# D1H register map
Vendor: Allwinner; File version: 1.0
Registers are 32-bit, read-write, reset 0x0 unless marked. A register's access mark holds for its fields unless they carry their own. Offsets are from the block's base; [hi:lo] are bit positions; {n}, {i} and the like mark numbered series; 'fields as' and 'values as' point back to an identical list.

## HS_TIMER — High Speed Timer
Base 0x03008000
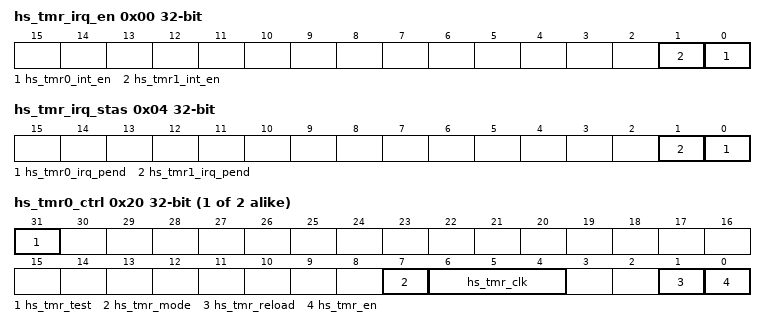
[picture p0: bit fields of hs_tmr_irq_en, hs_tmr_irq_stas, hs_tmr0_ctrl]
0x00 hs_tmr_irq_en — HS Timer IRQ Enable Register
  [n] hs_tmr{n}_int_en (n=0..1) — HSTimer Interrupt Enable
    0=DISABLED; 1=ENABLED
0x04 hs_tmr_irq_stas — HS Timer Status Register
  [n] hs_tmr{n}_irq_pend (n=0..1) write-1-clears — HSTimer IRQ Pending
    0=NO_EFFECT; 1=PENDING
{0x20+0x20*i} hs_tmr{i}_ctrl (i=0..1) — HS Timer Control Register
  [31] hs_tmr_test — Select the operating mode for HSTimer
    0=NORMAL; 1=TEST
  [7] hs_tmr_mode — Select the timing mode for HSTimer
    0=PERIODIC; 1=ONE_SHOT
  [6:4] hs_tmr_clk — Select the pre-scale for the HSTimer clock sources
    0=P1; 1=P2; 2=P4; 3=P8; 4=P16
  [1] hs_tmr_reload write-1-sets — HSTimer Reload
    0=NO_EFFECT; 1=RELOAD
  [0] hs_tmr_en — HSTimer Enable
    0=STOP_PAUSE; 1=START
{0x24+0x20*i} hs_tmr{i}_intv_lo (i=0..1) — HS Timer Interval Value Low Register
{0x28+0x20*i} hs_tmr{i}_intv_hi (i=0..1) — HS Timer Interval Value High Register
  [23:0] hs_tmr_intv_value_hi
{0x2C+0x20*i} hs_tmr{i}_curnt_lo (i=0..1) — HS Timer Current Value Low Register
{0x30+0x20*i} hs_tmr{i}_curnt_hi (i=0..1) — HS Timer Current Value High Register
  [23:0] hs_tmr_cur_value_hi

## PLIC — Platform Level Interrupt Control
Base 0x10000000
{0x0+4i} prio[{i}] (i=0..255) — Interrupt Priority Register
  [4:0] priority
    0=P0 (Priority 0 (never interrupt)); {v}=P{v} (Priority {v}) (v=1..31)
{0x1000+4i} ip[{i}] (i=0..8) — Interrupt Pending Register
{0x2000+4i} mie[{i}] (i=0..8) — Machine Mode Interrupt Enable Register
{0x2080+4i} sie[{i}] (i=0..8) — Supervisor Mode Interrupt Enable Register
0x1FFFFC ctrl — Control Register
  [0] ctrl — PLIC Control
    0=M (Only the machine mode can access to all registers in PLIC. Supervisor mode can only access the interrupt threshold register and the interrupt response/completion register.); 1=MS (The machine mode and the supervisor mode can access all registers. CTRL is accessible only in the machine mode.)
0x200000 mth — Machine Mode Priority Threshold Register
  fields as prio[0]
0x200004 mclaim — Machine Mode Claim/Complete Register
  [9:0] mclaim
0x201000 sth — Supervisor Mode Priority Threshold Register
  fields as prio[0]
0x201004 sclaim — Supervisor Mode Claim/Complete Register
  [9:0] sclaim

## THS — Thermal Sensor Controller
Base 0x02009400
0x00 ths_ctrl reset 0x1DF002F — THS Control Register
  [31:16] tacq — ADC acquire time . CLK_IN/(n + 1) . The default value is 2 us.
0x04 ths_en — THS Enable Register
  [0] ths_en — Enable temperature measurement sensor
    0=DISABLE; 1=ENABLE
0x08 ths_per reset 0x3A000 — THS Period Control Register
  [31:12] thermal_per — Temperature measurement period . 4096*(n + 1)/CLK_IN . The default value is 10 ms.
0x10 ths_data_intc — THS Data Interrupt Control Register
  [0] ths_data_irq_en — Enable the interrupt of sensor_data update . If enabled, when the measured sensor_data is updated, it will generate an interrupt.
    0=DISABLE; 1=ENABLE
0x14 ths_shut_intc — THS Shut Interrupt Control Register
  [0] shut_int_en — Enable the shutdown interrupt for the sensor
    0=DISABLE; 1=ENABLE
0x18 ths_alarm_intc — THS Alarm Interrupt Control Register
  [0] alarm_int_en — Enable the alarm interrupt for the sensor
    0=DISABLE; 1=ENABLE
0x20 ths_data_ints — THS Data Interrupt Status Register
  [0] ths_data_irq_sts write-1-clears — Indicates the pending status of the sensor's data interrupt. . Write 1 to clear the pending status.
    0=NO_EFFECT; 1=PENDING
0x24 ths_shut_ints — THS Shut Interrupt Status Register
  [0] shut_int_sts write-1-clears — Indicates the pending status of the sensor's shutdown interrupt. . Write 1 to clear the pending status.
    0=NO_EFFECT; 1=PENDING
0x28 ths_alarmo_ints — THS_ALARM0_INTS
  [0] alarm_off_sts write-1-clears — Alarm interrupt off pending for sensor . Write 1 to clear the pending status.
    0=NO_EFFECT; 1=PENDING
0x2C ths_alarm_ints — THS Alarm Interrupt Status Register
  [0] alarm_int_sts write-1-clears — Alarm interrupt pending for sensor . Write 1 to clear the pending status.
    0=NO_EFFECT; 1=PENDING
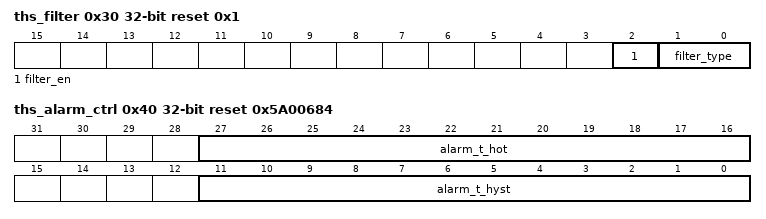
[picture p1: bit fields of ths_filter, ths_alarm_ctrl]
0x30 ths_filter reset 0x1 — THS Median Filter Control Register
  [2] filter_en — Filter enable
    0=DISABLE; 1=ENABLE
  [1:0] filter_type — Averaging filter type
    0=T2 (2); 1=T4 (4); 2=T8 (8); 3=T16 (16)
0x40 ths_alarm_ctrl reset 0x5A00684 — THS Alarm Threshold Control Register
  [27:16] alarm_t_hot — Thermal sensor alarm threshold for hot temperature
  [11:0] alarm_t_hyst — Thermal sensor alarm threshold for hysteresis temperature
0x80 ths_shutdown_ctrl reset 0x4E9 — THS Shutdown Threshold Control Register
  [11:0] shut_t_hot — Thermal sensor shutdown threshold for hot temperature
0xA0 ths_cdata reset 0x800 — THS Calibration Data
  [11:0] ths_cdata — Thermal sensor calibration data
0xC0 ths_data ro
  [11:0] ths_data — Temperature measurement data of sensor
